VERSION ""

NS_ :

BS_:

BU_: CELLBOARD HANDCART BMS_HV HANDCART MAINBOARD HANDCART MAINBOARD BMS_HV HANDCART BMS_HV CELLBOARD HANDCART BMS_HV HANDCART BMS_HV HANDCART CELLBOARD BMS_HV CELLBOARD HANDCART BMS_HV BMS_HV HANDCART BMS_HV MAINBOARD HANDCART BMS_HV MAINBOARD CELLBOARD BMS_HV HANDCART MAINBOARD HANDCART BMS_HV

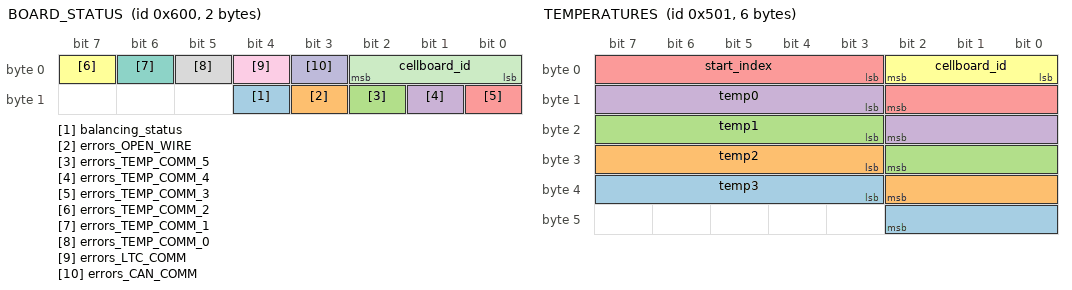
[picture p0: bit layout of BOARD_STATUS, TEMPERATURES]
BO_ 1536 BOARD_STATUS: 2 Vector__XXX
 SG_ balancing_status : 12|1@1+ (1,0) [0|1] "" Vector__XXX
 SG_ errors_OPEN_WIRE : 11|1@1+ (1,0) [0|0] "" Vector__XXX
 SG_ errors_TEMP_COMM_5 : 10|1@1+ (1,0) [0|0] "" Vector__XXX
 SG_ errors_TEMP_COMM_4 : 9|1@1+ (1,0) [0|0] "" Vector__XXX
 SG_ errors_TEMP_COMM_3 : 8|1@1+ (1,0) [0|0] "" Vector__XXX
 SG_ errors_TEMP_COMM_2 : 7|1@1+ (1,0) [0|0] "" Vector__XXX
 SG_ errors_TEMP_COMM_1 : 6|1@1+ (1,0) [0|0] "" Vector__XXX
 SG_ errors_TEMP_COMM_0 : 5|1@1+ (1,0) [0|0] "" Vector__XXX
 SG_ errors_LTC_COMM : 4|1@1+ (1,0) [0|0] "" Vector__XXX
 SG_ errors_CAN_COMM : 3|1@1+ (1,0) [0|0] "" Vector__XXX
 SG_ cellboard_id : 0|3@1+ (1,0) [0|7] "" Vector__XXX

BO_ 1281 TEMPERATURES: 6 Vector__XXX
 SG_ temp3 : 35|8@1+ (0.39215686274509803,-20) [-20|80] "" Vector__XXX
 SG_ temp2 : 27|8@1+ (0.39215686274509803,-20) [-20|80] "" Vector__XXX
 SG_ temp1 : 19|8@1+ (0.39215686274509803,-20) [-20|80] "" Vector__XXX
 SG_ temp0 : 11|8@1+ (0.39215686274509803,-20) [-20|80] "" Vector__XXX
 SG_ start_index : 3|8@1+ (1,0) [0|255] "" Vector__XXX
 SG_ cellboard_id : 0|3@1+ (1,0) [0|7] "" Vector__XXX

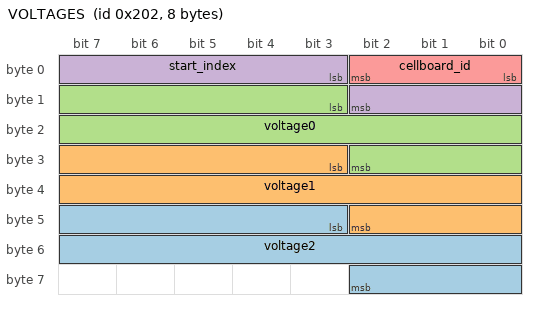
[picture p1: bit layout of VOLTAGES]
BO_ 514 VOLTAGES: 8 Vector__XXX
 SG_ voltage2 : 43|16@1+ (7.629510948348211e-05,0) [0|5] "" Vector__XXX
 SG_ voltage1 : 27|16@1+ (7.629510948348211e-05,0) [0|5] "" Vector__XXX
 SG_ voltage0 : 11|16@1+ (7.629510948348211e-05,0) [0|5] "" Vector__XXX
 SG_ start_index : 3|8@1+ (1,0) [0|255] "" Vector__XXX
 SG_ cellboard_id : 0|3@1+ (1,0) [0|7] "" Vector__XXX

BO_ 515 BALANCING: 4 Vector__XXX
 SG_ cells_CELL17 : 28|1@1+ (1,0) [0|0] "" Vector__XXX
 SG_ cells_CELL16 : 27|1@1+ (1,0) [0|0] "" Vector__XXX
 SG_ cells_CELL15 : 26|1@1+ (1,0) [0|0] "" Vector__XXX
 SG_ cells_CELL14 : 25|1@1+ (1,0) [0|0] "" Vector__XXX
 SG_ cells_CELL13 : 24|1@1+ (1,0) [0|0] "" Vector__XXX
 SG_ cells_CELL12 : 23|1@1+ (1,0) [0|0] "" Vector__XXX
 SG_ cells_CELL11 : 22|1@1+ (1,0) [0|0] "" Vector__XXX
 SG_ cells_CELL10 : 21|1@1+ (1,0) [0|0] "" Vector__XXX
 SG_ cells_CELL9 : 20|1@1+ (1,0) [0|0] "" Vector__XXX
 SG_ cells_CELL8 : 19|1@1+ (1,0) [0|0] "" Vector__XXX
 SG_ cells_CELL7 : 18|1@1+ (1,0) [0|0] "" Vector__XXX
 SG_ cells_CELL6 : 17|1@1+ (1,0) [0|0] "" Vector__XXX
 SG_ cells_CELL5 : 16|1@1+ (1,0) [0|0] "" Vector__XXX
 SG_ cells_CELL4 : 15|1@1+ (1,0) [0|0] "" Vector__XXX
 SG_ cells_CELL3 : 14|1@1+ (1,0) [0|0] "" Vector__XXX
 SG_ cells_CELL2 : 13|1@1+ (1,0) [0|0] "" Vector__XXX
 SG_ cells_CELL1 : 12|1@1+ (1,0) [0|0] "" Vector__XXX
 SG_ cells_CELL0 : 11|1@1+ (1,0) [0|0] "" Vector__XXX
 SG_ board_index : 3|8@1+ (1,0) [0|255] "" Vector__XXX
 SG_ cellboard_id : 0|3@1+ (1,0) [0|7] "" Vector__XXX

BO_ 10 FW_UPDATE: 2 Vector__XXX
 SG_ board_index : 3|8@1+ (1,0) [0|255] "" Vector__XXX
 SG_ cellboard_id : 0|3@1+ (1,0) [0|7] "" Vector__XXX

BO_ 16 FLASH_CELLBOARD_0_TX: 0 Vector__XXX

BO_ 17 FLASH_CELLBOARD_0_RX: 0 Vector__XXX

BO_ 18 FLASH_CELLBOARD_1_TX: 0 Vector__XXX

BO_ 19 FLASH_CELLBOARD_1_RX: 0 Vector__XXX

BO_ 20 FLASH_CELLBOARD_2_TX: 0 Vector__XXX

BO_ 21 FLASH_CELLBOARD_2_RX: 0 Vector__XXX

BO_ 22 FLASH_CELLBOARD_3_TX: 0 Vector__XXX

BO_ 23 FLASH_CELLBOARD_3_RX: 0 Vector__XXX

BO_ 24 FLASH_CELLBOARD_4_TX: 0 Vector__XXX

BO_ 25 FLASH_CELLBOARD_4_RX: 0 Vector__XXX

BO_ 26 FLASH_CELLBOARD_5_TX: 0 Vector__XXX

BO_ 27 FLASH_CELLBOARD_5_RX: 0 Vector__XXX

CM_ BO_ 1536 "Cellboard's status";
CM_ BO_ 1281 "Cells' temperatures";
CM_ BO_ 514 "Cells' voltages";
CM_ BO_ 515 "Set discharging status for cells";
CM_ BO_ 10 "Starts firmware update";

VAL_ 1536 balancing_status 0 "OFF" 1 "DISCHARGE" ;
VAL_ 1536 cellboard_id 0 "CELLBOARD_0" 1 "CELLBOARD_1" 2 "CELLBOARD_2" 3 "CELLBOARD_3" 4 "CELLBOARD_4" 5 "CELLBOARD_5" ;
VAL_ 1281 cellboard_id 0 "CELLBOARD_0" 1 "CELLBOARD_1" 2 "CELLBOARD_2" 3 "CELLBOARD_3" 4 "CELLBOARD_4" 5 "CELLBOARD_5" ;
VAL_ 514 cellboard_id 0 "CELLBOARD_0" 1 "CELLBOARD_1" 2 "CELLBOARD_2" 3 "CELLBOARD_3" 4 "CELLBOARD_4" 5 "CELLBOARD_5" ;
VAL_ 515 cellboard_id 0 "CELLBOARD_0" 1 "CELLBOARD_1" 2 "CELLBOARD_2" 3 "CELLBOARD_3" 4 "CELLBOARD_4" 5 "CELLBOARD_5" ;
VAL_ 10 cellboard_id 0 "CELLBOARD_0" 1 "CELLBOARD_1" 2 "CELLBOARD_2" 3 "CELLBOARD_3" 4 "CELLBOARD_4" 5 "CELLBOARD_5" ;
